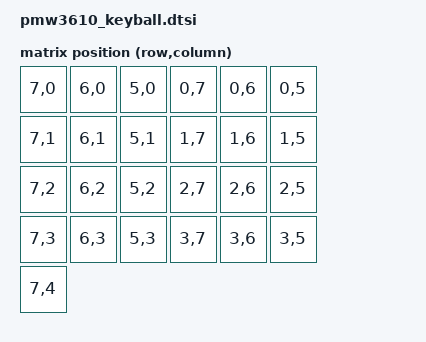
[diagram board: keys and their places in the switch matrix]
// This file was generated from a template. Edit it to match your keyboard.
// See https://zmk.dev/docs/development/hardware-integration/new-shield for more
// instructions.

#include <dt-bindings/zmk/matrix_transform.h>

#include "pmw3610_keyball-layouts.dtsi"

#define RCOL_OFFSET (3)
#define RROW_OFFSET (5)
#define RC_R(row, col) (RC(row + RROW_OFFSET, col + RCOL_OFFSET))

/ {
    chosen {
        zmk,physical-layout = &default_layout;
    };

    kscan: kscan {
        // If the hardware does not use a switch matrix, change this to the
        // appropriate driver and update the properties below to match.
        // See https://zmk.dev/docs/config/kscan for supported key scan drivers.
        // compatible = "zmk,kscan-gpio-matrix";
        compatible = "zmk,kscan-gpio-charlieplex";

        // Set this to "col2row" or "row2col" to match the hardware. If using
        // "row2col", change the col-gpios in the _left.overlay and _right.overlay
        // files to (GPIO_ACTIVE_HIGH | GPIO_PULL_DOWN) and the row-gpios here to
        // GPIO_ACTIVE_HIGH.
        // diode-direction = "col2row";
        wakeup-source;

        // Replace these comments with the GPIO pins in the matrix.
        // See https://zmk.dev/docs/development/hardware-integration/new-shield#shield-overlays
        // row-gpios
        //     = <&xiao_d 0 (GPIO_ACTIVE_HIGH | GPIO_PULL_DOWN)>
        //     , <&xiao_d 1 (GPIO_ACTIVE_HIGH | GPIO_PULL_DOWN)>
        //     ;
        // col-gpios
        //     = <&xiao_d 2 GPIO_ACTIVE_HIGH>
        //     , <&xiao_d 3 GPIO_ACTIVE_HIGH>
        //     ;
        gpios
            = <&xiao_d  0 GPIO_ACTIVE_HIGH> // ROW1 (0)
            , <&xiao_d  1 GPIO_ACTIVE_HIGH> // ROW2 (1)
            , <&xiao_d  2 GPIO_ACTIVE_HIGH> // ROW3 (2)
            , <&xiao_d  3 GPIO_ACTIVE_HIGH> // ROW4 (3)
            , <&xiao_d 10 GPIO_ACTIVE_HIGH> // ROW5 (4)
            , <&xiao_d  6 GPIO_ACTIVE_HIGH> // COL1 (5)
            , <&xiao_d  5 GPIO_ACTIVE_HIGH> // COL2 (6)
            , <&xiao_d  4 GPIO_ACTIVE_HIGH> // COL3 (7)
            ;
    };

    default_transform: default_transform {
        // See https://zmk.dev/docs/development/hardware-integration/new-shield#matrix-transform
        // for how to configure this
        compatible = "zmk,matrix-transform";
        columns = <12>;
        rows = <5>;

        map = <
            RC(7, 0) RC(6, 0) RC(5, 0) RC(0, 7) RC(0, 6) RC(0, 5)   RC_R(7, 0) RC_R(6, 0) RC_R(5, 0) RC_R(0, 7) RC_R(0, 6) RC_R(0, 5) 
            RC(7, 1) RC(6, 1) RC(5, 1) RC(1, 7) RC(1, 6) RC(1, 5)   RC_R(7, 1) RC_R(6, 1) RC_R(5, 1) RC_R(1, 7) RC_R(1, 6) RC_R(1, 5) 
            RC(7, 2) RC(6, 2) RC(5, 2) RC(2, 7) RC(2, 6) RC(2, 5)   RC_R(7, 2) RC_R(6, 2) RC_R(5, 2) RC_R(2, 7) RC_R(2, 6) RC_R(2, 5) 
            RC(7, 3) RC(6, 3) RC(5, 3) RC(3, 7) RC(3, 6) RC(3, 5)   RC_R(7, 3) RC_R(6, 3) RC_R(5, 3) RC_R(3, 7) RC_R(3, 6) RC_R(3, 5) 
            RC(7, 4)
        >;
    };
};
